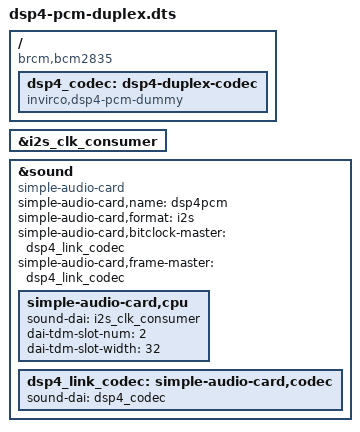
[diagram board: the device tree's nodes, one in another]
// dsp4-pcm-duplex.dts — TRUE DUPLEX I2S soundcard for the DSP4 bench CM4.
//
// Replaces dsp4-pcm-slave.dts, which works one direction at a time and
// scrambles when both run. Measured 2026-09-08 with that overlay loaded:
// /proc/asound/pcm shows TWO devices sharing one CPU DAI --
//     00-00 bcm2835-i2s-dir-hifi ... capture 1
//     00-01 bcm2835-i2s-dit-hifi ... playback 1
// -- capture alone is stable and playback alone reaches the DSP, but a
// per-sample counter played and captured together comes back with values
// under ~200 across 20,000 frames instead of climbing to 48,000, dominant
// step -191, with ALSA reporting no under/overrun once period and buffer
// are pinned. Two PCM devices are not a duplex device: each open programs
// the same bcm2835-i2s block independently, and the second one to start
// re-programs the first's frame phase.
//
// WHY THE OLD OVERLAY HAD TO DO THAT. `linux,spdif-dit` declares a
// PLAYBACK-only DAI and `linux,spdif-dir` a CAPTURE-only one, so no single
// dai-link built from them can carry both directions -- simple-audio-card
// takes the intersection of what the CPU and CODEC DAIs declare.
//
// THE CODEC IS OURS, `invirco,dsp4-pcm-dummy`, and it is forty lines of
// DAI declaration in `dsp4-pcm-dummy/` next to this file. Four candidates
// were measured on the bench 2026-09-08 before writing one, and the
// requirement they failed is now fully stated: the DAI must declare
// PLAYBACK AND CAPTURE, S32_LE, AND 192 kHz.
//
//   linux,spdif-dit +    the overlay this replaces. Right rate, right
//   linux,spdif-dir      format, but one direction each, so they need two
//   (two dai-links)      dai-links sharing one bcm2835-i2s block -- and
//                        the second stream to start re-programs the
//                        first's framing. Capture alone is stable and
//                        playback alone reaches the DSP; both together
//                        scramble.
//
//   asahi-kasei,ak4554   ONE dai-link and a REAL duplex device
//                        ("00-00 ... playback 1 : capture 1"), which is
//                        what proved the shape is right -- and its DAI
//                        declares S16_LE only ("arecord -f S32_LE" ->
//                        "Available formats: - S16_LE"). The lanes are
//                        32-bit words; 16 bits in a 32-bit slot is a
//                        truncation, not a link.
//
//   dit + dir as two     simple-audio-card multi-codec on ONE link. It
//   codecs on ONE link   instantiates and comes out CAPTURE ONLY: the
//                        playback-only codec loses.
//
//   google,voicehat      Both directions, S32_LE -- and 48 kHz ONLY. With
//                        the hub's pin ruling (below) it probes and gives
//                        a real duplex device, and then ALSA clamps
//                        192 kHz to 48 kHz and the capture overruns by
//                        ~1.6 s: a known word played as 0x00001000,
//                        0x00010000 and 0x00100000 all come back as the
//                        same unrelated constant (0x11E7DF98 /
//                        0x11E7DF40 / 0x11E7E510). THE RATE IS NOT
//                        NEGOTIABLE: `shared/dsp4-logic/slot-map.csv`
//                        lane A_I6 says LOGIC "regroups 4 Pi frames per
//                        DSP frame", so the Pi frame is 2 slots x 32 bits
//                        at 192 kHz.
//
// THE PIN RULING IS RECORDED AND NO LONGER NEEDED. The hub ruled on
// 2026-09-08 (mx26 `src/hw/d24-hw-pins.csv`) that CM4 GPIO17 = CS6 is the
// dummy `sdmode-gpios` for `google,voicehat`: CS5/CS6 are spare SPI chip
// selects provisioned for up to eight DSPs, on D24 only CS1/CS2 are chip
// selects and CS3/CS4 are RDY, CS6 reaches the DSP board connector
// (J17 = P[27-34]) and terminates at unfitted pads, and driving it high
// is the CS idle level. That ruling was applied and it WORKED -- voicehat
// probed and the card came up. It is voicehat's RATE, not its pin, that
// disqualifies it, so `dsp4-pcm-dummy` needs no GPIO at all.
//
// Everything else is unchanged from the overlay it replaces, and it has
// to be: the LOGIC CPLD masters pcm_clk (3.072 MHz) and pcm_fs (48 kHz),
// so the Pi is an I2S SLAVE and bitclock-master/frame-master point at the
// CODEC side of the link, not the cpu side. 32-bit slots, 2 per frame,
// because the DSP4 lanes carry 32-bit words and the rung-2 check is
// bit-exact across all 32.
/dts-v1/;
/plugin/;

/ {
    compatible = "brcm,bcm2835";

    fragment@0 {
        target = <&i2s_clk_consumer>;
        __overlay__ { status = "okay"; };
    };

    fragment@1 {
        target-path = "/";
        __overlay__ {
            dsp4_codec: dsp4-duplex-codec {
                compatible = "invirco,dsp4-pcm-dummy";
                #sound-dai-cells = <0>;
                status = "okay";
            };
        };
    };

    fragment@2 {
        target = <&sound>;
        __overlay__ {
            compatible = "simple-audio-card";
            simple-audio-card,name = "dsp4pcm";
            status = "okay";

            simple-audio-card,format = "i2s";
            simple-audio-card,bitclock-master = <&dsp4_link_codec>;
            simple-audio-card,frame-master = <&dsp4_link_codec>;

            simple-audio-card,cpu {
                sound-dai = <&i2s_clk_consumer>;
                dai-tdm-slot-num = <2>;
                dai-tdm-slot-width = <32>;
            };
            dsp4_link_codec: simple-audio-card,codec {
                sound-dai = <&dsp4_codec>;
            };
        };
    };
};
